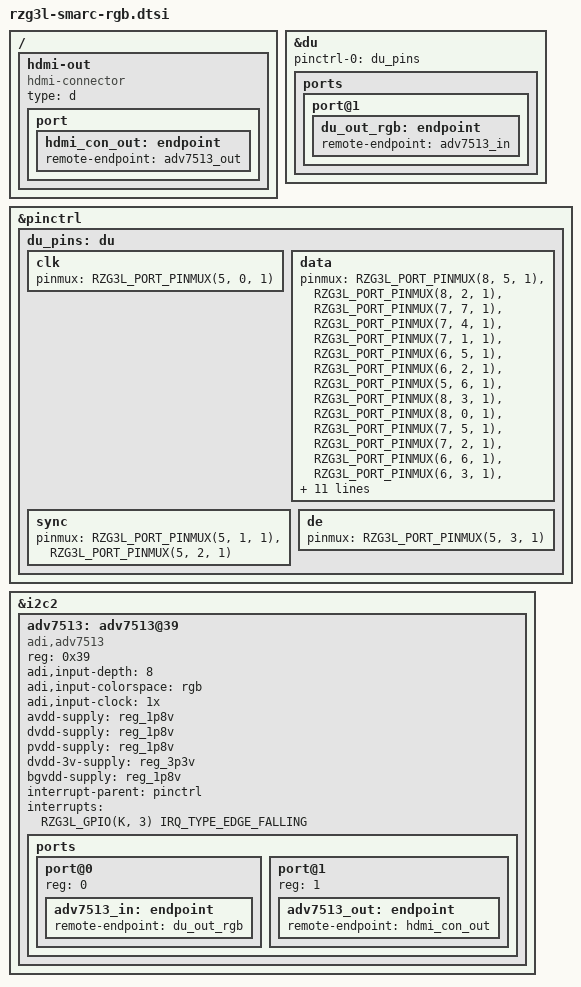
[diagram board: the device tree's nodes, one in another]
// SPDX-License-Identifier: (GPL-2.0-only OR BSD-2-Clause)
/*
 * Device Tree Source for the RZ SMARC RGB-to-HDMI 2 sub-board
 *
 * Copyright (C) 2025 Renesas Electronics Corp.
 */

/ {
	hdmi-out {
		compatible = "hdmi-connector";
		type = "d";

		port {
			hdmi_con_out: endpoint {
				remote-endpoint = <&adv7513_out>;
			};
		};
	};
};

&du {
	pinctrl-0 = <&du_pins>;
	pinctrl-names = "default";

	status = "okay";

	ports {
		port@1 {
			du_out_rgb: endpoint {
				remote-endpoint = <&adv7513_in>;
			};
		};
	};
};

&pinctrl {
	du_pins: du {
		clk {
			pinmux = <RZG3L_PORT_PINMUX(5, 0, 1)>; /* CLK */
		};

		data {
			pinmux = <RZG3L_PORT_PINMUX(8, 5, 1)>, /* LCD_R0 */
				 <RZG3L_PORT_PINMUX(8, 2, 1)>, /* LCD_R1 */
				 <RZG3L_PORT_PINMUX(7, 7, 1)>, /* LCD_R2 */
				 <RZG3L_PORT_PINMUX(7, 4, 1)>, /* LCD_R3 */
				 <RZG3L_PORT_PINMUX(7, 1, 1)>, /* LCD_R4 */
				 <RZG3L_PORT_PINMUX(6, 5, 1)>, /* LCD_R5 */
				 <RZG3L_PORT_PINMUX(6, 2, 1)>, /* LCD_R6 */
				 <RZG3L_PORT_PINMUX(5, 6, 1)>, /* LCD_R7 */
				 <RZG3L_PORT_PINMUX(8, 3, 1)>, /* LCD_G0 */
				 <RZG3L_PORT_PINMUX(8, 0, 1)>, /* LCD_G1 */
				 <RZG3L_PORT_PINMUX(7, 5, 1)>, /* LCD_G2 */
				 <RZG3L_PORT_PINMUX(7, 2, 1)>, /* LCD_G3 */
				 <RZG3L_PORT_PINMUX(6, 6, 1)>, /* LCD_G4 */
				 <RZG3L_PORT_PINMUX(6, 3, 1)>, /* LCD_G5 */
				 <RZG3L_PORT_PINMUX(6, 0, 1)>, /* LCD_G6 */
				 <RZG3L_PORT_PINMUX(5, 4, 1)>, /* LCD_G7 */
				 <RZG3L_PORT_PINMUX(8, 4, 1)>, /* LCD_B0 */
				 <RZG3L_PORT_PINMUX(8, 1, 1)>, /* LCD_B1 */
				 <RZG3L_PORT_PINMUX(7, 6, 1)>, /* LCD_B2 */
				 <RZG3L_PORT_PINMUX(7, 3, 1)>, /* LCD_B3 */
				 <RZG3L_PORT_PINMUX(7, 0, 1)>, /* LCD_B4 */
				 <RZG3L_PORT_PINMUX(6, 4, 1)>, /* LCD_B5 */
				 <RZG3L_PORT_PINMUX(6, 1, 1)>, /* LCD_B6 */
				 <RZG3L_PORT_PINMUX(5, 5, 1)>; /* LCD_B7 */
				 power-source = <1800>;
		};

		sync {
			pinmux = <RZG3L_PORT_PINMUX(5, 1, 1)>, /* HSYNC */
				 <RZG3L_PORT_PINMUX(5, 2, 1)>; /* VSYNC */
		};

		de {
			pinmux = <RZG3L_PORT_PINMUX(5, 3, 1)>; /* DE */
		};
	};
};

&i2c2 {
	adv7513: adv7513@39 {
		compatible = "adi,adv7513";
		reg = <0x39>;

		adi,input-depth = <8>;
		adi,input-colorspace = "rgb";
		adi,input-clock = "1x";

		avdd-supply = <&reg_1p8v>;
		dvdd-supply = <&reg_1p8v>;
		pvdd-supply = <&reg_1p8v>;
		dvdd-3v-supply = <&reg_3p3v>;
		bgvdd-supply = <&reg_1p8v>;

		interrupt-parent = <&pinctrl>;
		interrupts = <RZG3L_GPIO(K, 3) IRQ_TYPE_EDGE_FALLING>;

		ports {
			#address-cells = <1>;
			#size-cells = <0>;

			port@0 {
				reg = <0>;

				adv7513_in: endpoint {
					remote-endpoint = <&du_out_rgb>;
				};
			};

			port@1 {
				reg = <1>;

				adv7513_out: endpoint {
					remote-endpoint = <&hdmi_con_out>;
				};
			};
		};
	};
};
